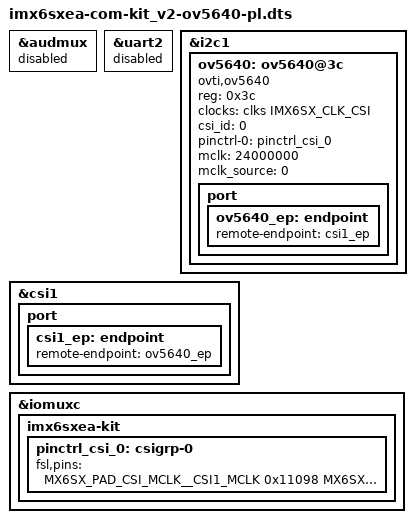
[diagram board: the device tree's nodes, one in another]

/*
 * Copyright (C) 2018 Embedded Artists AB
 *
 * This program is free software; you can redistribute it and/or modify
 * it under the terms of the GNU General Public License version 2 as
 * published by the Free Software Foundation.
 */

#include "imx6sxea-com-kit_v2.dts"

&audmux {
	status = "disabled";
};

&uart2 {
	status = "disabled";
};

&i2c1 {

	ov5640: ov5640@3c {
		compatible = "ovti,ov5640";
		reg = <0x3c>;
		clocks = <&clks IMX6SX_CLK_CSI>;
		clock-names = "csi_mclk";
		csi_id = <0>;
		pinctrl-names = "default";
		pinctrl-0 = <&pinctrl_csi_0>;
		mclk = <24000000>;
		mclk_source = <0>;
		port {
			ov5640_ep: endpoint {
				remote-endpoint = <&csi1_ep>;
			};
		};
	};

};

&csi1 {
	status = "okay";

	port {
		csi1_ep: endpoint {
			remote-endpoint = <&ov5640_ep>;
		};
	};
};


&iomuxc {

	imx6sxea-kit {
		pinctrl_csi_0: csigrp-0 {
			fsl,pins = <
				MX6SX_PAD_CSI_MCLK__CSI1_MCLK           0x11098
				MX6SX_PAD_CSI_PIXCLK__CSI1_PIXCLK	0x110b0
				MX6SX_PAD_CSI_VSYNC__CSI1_VSYNC         0x110b0
				MX6SX_PAD_CSI_HSYNC__CSI1_HSYNC         0x110b0
				MX6SX_PAD_CSI_DATA00__CSI1_DATA_2	0x110b0
				MX6SX_PAD_CSI_DATA01__CSI1_DATA_3       0x110b0
				MX6SX_PAD_CSI_DATA02__CSI1_DATA_4       0x110b0
				MX6SX_PAD_CSI_DATA03__CSI1_DATA_5       0x110b0
				MX6SX_PAD_CSI_DATA04__CSI1_DATA_6       0x110b0
				MX6SX_PAD_CSI_DATA05__CSI1_DATA_7       0x110b0
				MX6SX_PAD_CSI_DATA06__CSI1_DATA_8	0x110b0
				MX6SX_PAD_CSI_DATA07__CSI1_DATA_9	0x110b0

			>;
		};

	};
};

